# colorlight register map
Vendor: litex
Registers are 32-bit, read-write, reset 0x0 unless marked. A register's access mark holds for its fields unless they carry their own. Offsets are from the block's base; [hi:lo] are bit positions; {n}, {i} and the like mark numbered series.

## XBARPERF
Base 0xF0002000
{0x0+4i} M{i} (i=0..5)

## CTRL
Base 0xF0002800
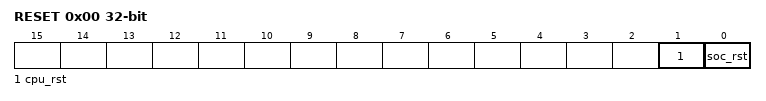
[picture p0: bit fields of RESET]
0x00 RESET
  [1] cpu_rst — Write `1` to this register to reset the CPU(s) of the SoC (Hold Reset)
  [0] soc_rst — Write `1` to this register to reset the full SoC (Pulse Reset)
0x04 SCRATCH reset 0x12345678 — Use this register as a scratch space to verify that software read/write accesses to the Wishbone/CSR bus are working correctly. The initial reset value of 0x12345678 can be used to verify endianness.
0x08 BUS_ERRORS — Total number of Wishbone bus errors (timeouts) since start.

## ETHPHY
Base 0xF0003800
0x00 CRG_RESET
  [0] crg_reset
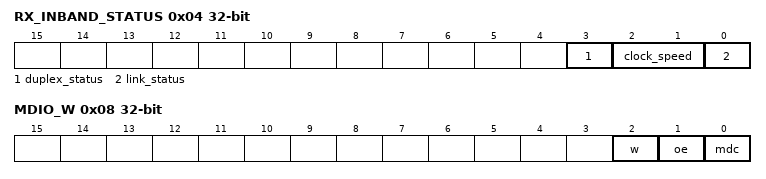
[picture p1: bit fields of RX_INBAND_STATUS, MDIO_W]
0x04 RX_INBAND_STATUS
  [3] duplex_status, [2:1] clock_speed, [0] link_status
0x08 MDIO_W
  [2] w, [1] oe, [0] mdc
0x0C MDIO_R
  [0] r

## HUB75_PALETTE
Base 0xF0004000
0x00 HUB75_PALETTE — 32 x 512-bit memory

## IDENTIFIER_MEM
Base 0xF0005000
0x00 IDENTIFIER_MEM — 8 x 67-bit memory
  [7:0] identifier_mem

## SDRAM
Base 0xF0005800
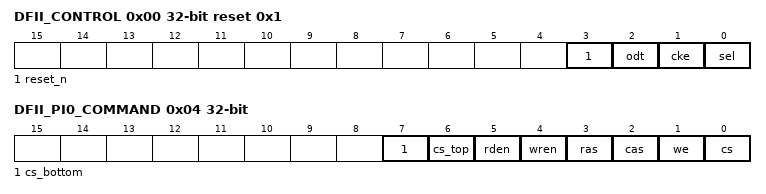
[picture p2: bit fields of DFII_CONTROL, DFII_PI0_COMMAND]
0x00 DFII_CONTROL reset 0x1 — Control DFI signals common to all phases
  [3] reset_n — DFI clock reset bus
  [2] odt — DFI on-die termination bus
  [1] cke — DFI clock enable bus
  [0] sel
0x04 DFII_PI0_COMMAND — Control DFI signals on a single phase
  [7] cs_bottom — DFI chip select bus for bottom half only
  [6] cs_top — DFI chip select bus for top half only
  [5] rden — DFI read data enable bus
  [4] wren — DFI write data enable bus
  [3] ras — DFI row address strobe bus
  [2] cas — DFI column address strobe bus
  [1] we — DFI write enable bus
  [0] cs — DFI chip select bus
0x08 DFII_PI0_COMMAND_ISSUE
  [0] dfii_pi0_command_issue
0x0C DFII_PI0_ADDRESS — DFI address bus
  [10:0] dfii_pi0_address
0x10 DFII_PI0_BADDRESS — DFI bank address bus
  [0] dfii_pi0_baddress
0x14 DFII_PI0_WRDATA — DFI write data bus
0x18 DFII_PI0_RDDATA — DFI read data bus

## TIMER0
Base 0xF0006000
0x00 LOAD — Load value when Timer is (re-)enabled. In One-Shot mode, the value written to this register specifies the Timer's duration in clock cycles.
0x04 RELOAD — Reload value when Timer reaches ``0``. In Periodic mode, the value written to this register specify the Timer's period in clock cycles.
0x08 EN — Enable flag of the Timer. Set this flag to ``1`` to enable/start the Timer. Set to ``0`` to disable the Timer.
  [0] en
0x0C UPDATE_VALUE — Update trigger for the current countdown value. A write to this register latches the current countdown value to ``value`` register.
  [0] update_value
0x10 VALUE — Latched countdown value. This value is updated by writing to ``update_value``.
0x14 EV_STATUS — This register contains the current raw level of the zero event trigger. Writes to this register have no effect.
  [0] zero — Level of the ``zero`` event
0x18 EV_PENDING — When a zero event occurs, the corresponding bit will be set in this register. To clear the Event, set the corresponding bit in this register.
  [0] zero — `1` if a `zero` event occurred. This Event is triggered on **rising** edge.
0x1C EV_ENABLE — This register enables the corresponding zero events. Write a ``0`` to this register to disable individual events.
  [0] zero — Write a ``1`` to enable the ``zero`` Event

## UART
Base 0xF0006800
0x00 RXTX
  [7:0] rxtx
0x04 TXFULL — TX FIFO Full.
  [0] txfull
0x08 RXEMPTY — RX FIFO Empty.
  [0] rxempty
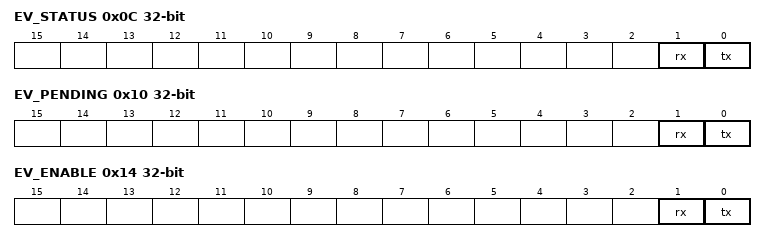
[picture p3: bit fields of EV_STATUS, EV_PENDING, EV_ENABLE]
0x0C EV_STATUS — This register contains the current raw level of the rx event trigger. Writes to this register have no effect.
  [1] rx — Level of the ``rx`` event
  [0] tx — Level of the ``tx`` event
0x10 EV_PENDING — When a rx event occurs, the corresponding bit will be set in this register. To clear the Event, set the corresponding bit in this register.
  [1] rx — `1` if a `rx` event occurred. This Event is **level triggered** when the signal is **high**.
  [0] tx — `1` if a `tx` event occurred. This Event is **level triggered** when the signal is **high**.
0x14 EV_ENABLE — This register enables the corresponding rx events. Write a ``0`` to this register to disable individual events.
  [1] rx — Write a ``1`` to enable the ``rx`` Event
  [0] tx — Write a ``1`` to enable the ``tx`` Event
0x18 TXEMPTY — TX FIFO Empty.
  [0] txempty
0x1C RXFULL — RX FIFO Full.
  [0] rxfull

## ETHMEM
Base 0x80000000
{0x0+i} RX_BUFFER_0[{i}] (i=0..2047) 8-bit ro — rx buffers
  [7:0] rx_buffer_0
{0x800+i} RX_BUFFER_1[{i}] (i=0..2047) 8-bit ro — rx buffers
  [7:0] rx_buffer_1
{0x1000+i} TX_BUFFER_0[{i}] (i=0..2047) 8-bit — tx buffers
  [7:0] tx_buffer_0
{0x1800+i} TX_BUFFER_1[{i}] (i=0..2047) 8-bit — tx buffers
  [7:0] tx_buffer_1
